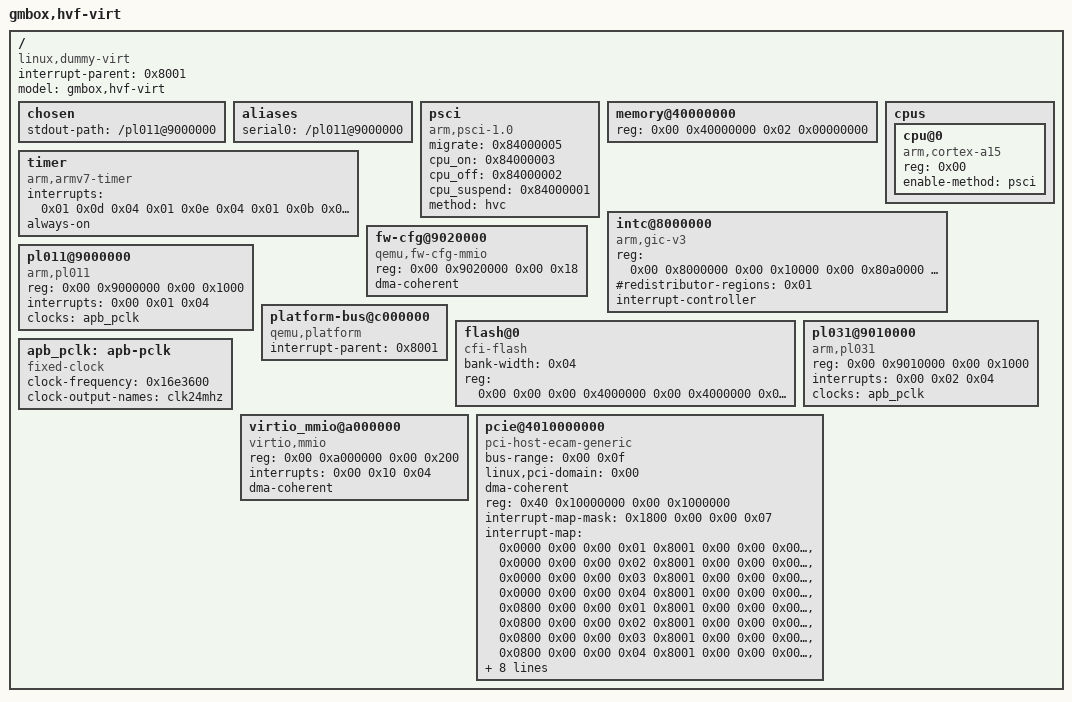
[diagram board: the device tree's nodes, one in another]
/dts-v1/;

/ {
	interrupt-parent = <0x8001>;
	#size-cells = <0x02>;
	#address-cells = <0x02>;
	model = "gmbox,hvf-virt";
	compatible = "linux,dummy-virt";

	chosen {
		stdout-path = "/pl011@9000000";
	};

	aliases {
		serial0 = "/pl011@9000000";
	};

	psci {
		migrate = <0x84000005>;
		cpu_on = <0x84000003>;
		cpu_off = <0x84000002>;
		cpu_suspend = <0x84000001>;
		method = "hvc";
		compatible = "arm,psci-1.0", "arm,psci-0.2", "arm,psci";
	};

	memory@40000000 {
		device_type = "memory";
		reg = <0x00 0x40000000 0x02 0x00000000>;
	};

	cpus {
		#size-cells = <0x00>;
		#address-cells = <0x01>;

		cpu@0 {
			device_type = "cpu";
			compatible = "arm,cortex-a15";
			reg = <0x00>;
			enable-method = "psci";
		};
	};

	timer {
		interrupts = <0x01 0x0d 0x04 0x01 0x0e 0x04 0x01 0x0b 0x04 0x01 0x0a 0x04>;
		always-on;
		compatible = "arm,armv7-timer";
	};

	intc@8000000 {
		phandle = <0x8001>;
		reg = <0x00 0x8000000 0x00 0x10000 0x00 0x80a0000 0x00 0xf60000>;
		#redistributor-regions = <0x01>;
		compatible = "arm,gic-v3";
		ranges;
		#size-cells = <0x02>;
		#address-cells = <0x02>;
		interrupt-controller;
		#interrupt-cells = <0x03>;
	};

	pl011@9000000 {
		compatible = "arm,pl011", "arm,primecell";
		reg = <0x00 0x9000000 0x00 0x1000>;
		interrupts = <0x00 0x01 0x04>;
		clock-names = "uartclk", "apb_pclk";
		clocks = <&apb_pclk>;
	};

	fw-cfg@9020000 {
		compatible = "qemu,fw-cfg-mmio";
		reg = <0x00 0x9020000 0x00 0x18>;
		dma-coherent;
	};

	platform-bus@c000000 {
		compatible = "qemu,platform", "simple-bus";
		interrupt-parent = <0x8001>;
		ranges = <0x00 0x00 0xc000000 0x2000000>;
		#address-cells = <0x01>;
		#size-cells = <0x01>;
	};

	flash@0 {
		bank-width = <0x04>;
		reg = <0x00 0x00 0x00 0x4000000 0x00 0x4000000 0x00 0x4000000>;
		compatible = "cfi-flash";
	};

	pl031@9010000 {
		compatible = "arm,pl031", "arm,primecell";
		reg = <0x00 0x9010000 0x00 0x1000>;
		interrupts = <0x00 0x02 0x04>;
		clock-names = "apb_pclk";
		clocks = <&apb_pclk>;
	};

	apb_pclk: apb-pclk {
		compatible = "fixed-clock";
		#clock-cells = <0x00>;
		clock-frequency = <0x16e3600>;
		clock-output-names = "clk24mhz";
	};

	virtio_mmio@a000000 {
		compatible = "virtio,mmio";
		reg = <0x00 0xa000000 0x00 0x200>;
		interrupts = <0x00 0x10 0x04>;
		dma-coherent;
	};

	pcie@4010000000 {
		compatible = "pci-host-ecam-generic";
		device_type = "pci";
		bus-range = <0x00 0x0f>;
		#interrupt-cells = <0x01>;
		#size-cells = <0x02>;
		#address-cells = <0x03>;
		linux,pci-domain = <0x00>;
		dma-coherent;
		reg = <0x40 0x10000000 0x00 0x1000000>;
		/* No PCI IO: Arm GCD has no IO map, AddIoSpace ASSERTs. MMIO32 only. */
		ranges = <0x02000000 0x00 0x10000000 0x00 0x10000000 0x00 0x2eff0000>;
		interrupt-map-mask = <0x1800 0x00 0x00 0x07>;
		interrupt-map = <0x0000 0x00 0x00 0x01 0x8001 0x00 0x00 0x00 0x03 0x04>,
				<0x0000 0x00 0x00 0x02 0x8001 0x00 0x00 0x00 0x04 0x04>,
				<0x0000 0x00 0x00 0x03 0x8001 0x00 0x00 0x00 0x05 0x04>,
				<0x0000 0x00 0x00 0x04 0x8001 0x00 0x00 0x00 0x06 0x04>,
				<0x0800 0x00 0x00 0x01 0x8001 0x00 0x00 0x00 0x04 0x04>,
				<0x0800 0x00 0x00 0x02 0x8001 0x00 0x00 0x00 0x05 0x04>,
				<0x0800 0x00 0x00 0x03 0x8001 0x00 0x00 0x00 0x06 0x04>,
				<0x0800 0x00 0x00 0x04 0x8001 0x00 0x00 0x00 0x03 0x04>,
				<0x1000 0x00 0x00 0x01 0x8001 0x00 0x00 0x00 0x05 0x04>,
				<0x1000 0x00 0x00 0x02 0x8001 0x00 0x00 0x00 0x06 0x04>,
				<0x1000 0x00 0x00 0x03 0x8001 0x00 0x00 0x00 0x03 0x04>,
				<0x1000 0x00 0x00 0x04 0x8001 0x00 0x00 0x00 0x04 0x04>,
				<0x1800 0x00 0x00 0x01 0x8001 0x00 0x00 0x00 0x06 0x04>,
				<0x1800 0x00 0x00 0x02 0x8001 0x00 0x00 0x00 0x03 0x04>,
				<0x1800 0x00 0x00 0x03 0x8001 0x00 0x00 0x00 0x04 0x04>,
				<0x1800 0x00 0x00 0x04 0x8001 0x00 0x00 0x00 0x05 0x04>;
	};
};
